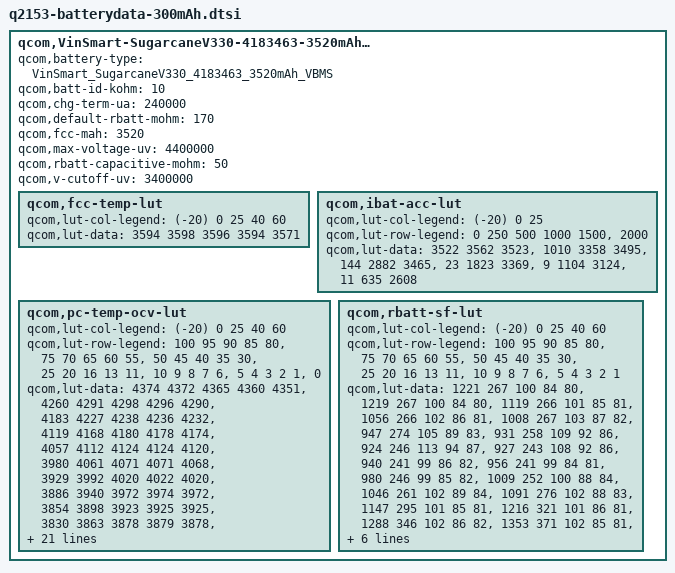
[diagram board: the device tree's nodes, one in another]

qcom,VinSmart-SugarcaneV330-4183463-3520mAh-VBMS-batterydata {
	qcom,battery-type = "VinSmart_SugarcaneV330_4183463_3520mAh_VBMS";
	qcom,batt-id-kohm = <10>;
	qcom,chg-term-ua = <240000>;
	qcom,default-rbatt-mohm = <170>;
	qcom,fcc-mah = <3520>;
	qcom,max-voltage-uv = <4400000>;
	qcom,rbatt-capacitive-mohm = <50>;
	qcom,v-cutoff-uv = <3400000>;

	qcom,fcc-temp-lut {
		qcom,lut-col-legend = <(-20) 0 25 40 60>;
		qcom,lut-data = <3594 3598 3596 3594 3571>;
	};

	qcom,ibat-acc-lut {
		qcom,lut-col-legend = <(-20) 0 25>;
		qcom,lut-row-legend = <0 250 500 1000 1500>,
					<2000>;
		qcom,lut-data = <3522 3562 3523>,
				<1010 3358 3495>,
				<144 2882 3465>,
				<23 1823 3369>,
				<9 1104 3124>,
				<11 635 2608>;
	};

	qcom,pc-temp-ocv-lut {
		qcom,lut-col-legend = <(-20) 0 25 40 60>;
		qcom,lut-row-legend = <100 95 90 85 80>,
					<75 70 65 60 55>,
					<50 45 40 35 30>,
					<25 20 16 13 11>,
					<10 9 8 7 6>,
					<5 4 3 2 1>,
					<0>;
		qcom,lut-data = <4374 4372 4365 4360 4351>,
				<4260 4291 4298 4296 4290>,
				<4183 4227 4238 4236 4232>,
				<4119 4168 4180 4178 4174>,
				<4057 4112 4124 4124 4120>,
				<3980 4061 4071 4071 4068>,
				<3929 3992 4020 4022 4020>,
				<3886 3940 3972 3974 3972>,
				<3854 3898 3923 3925 3925>,
				<3830 3863 3878 3879 3878>,
				<3811 3833 3846 3846 3846>,
				<3794 3810 3822 3822 3822>,
				<3779 3793 3802 3802 3802>,
				<3764 3780 3784 3784 3783>,
				<3750 3768 3769 3766 3760>,
				<3734 3754 3752 3744 3733>,
				<3716 3734 3734 3724 3712>,
				<3698 3714 3714 3704 3692>,
				<3682 3698 3694 3685 3674>,
				<3668 3690 3687 3680 3669>,
				<3660 3686 3686 3678 3668>,
				<3650 3682 3684 3677 3666>,
				<3636 3676 3682 3674 3664>,
				<3622 3671 3677 3670 3659>,
				<3604 3660 3668 3660 3646>,
				<3580 3638 3642 3628 3614>,
				<3549 3596 3595 3582 3568>,
				<3502 3541 3536 3522 3508>,
				<3434 3462 3456 3435 3428>,
				<3316 3340 3326 3310 3308>,
				<3000 3000 3000 3000 3000>;
	};

	qcom,rbatt-sf-lut {
		qcom,lut-col-legend = <(-20) 0 25 40 60>;
		qcom,lut-row-legend = <100 95 90 85 80>,
					<75 70 65 60 55>,
					<50 45 40 35 30>,
					<25 20 16 13 11>,
					<10 9 8 7 6>,
					<5 4 3 2 1>;
		qcom,lut-data = <1221 267 100 84 80>,
				<1219 267 100 84 80>,
				<1119 266 101 85 81>,
				<1056 266 102 86 81>,
				<1008 267 103 87 82>,
				<947 274 105 89 83>,
				<931 258 109 92 86>,
				<924 246 113 94 87>,
				<927 243 108 92 86>,
				<940 241 99 86 82>,
				<956 241 99 84 81>,
				<980 246 99 85 82>,
				<1009 252 100 88 84>,
				<1046 261 102 89 84>,
				<1091 276 102 88 83>,
				<1147 295 101 85 81>,
				<1216 321 101 86 81>,
				<1288 346 102 86 82>,
				<1353 371 102 85 81>,
				<1384 382 102 86 82>,
				<1519 399 104 87 82>,
				<1718 420 106 89 85>,
				<1961 447 108 91 87>,
				<2307 480 112 94 89>,
				<2798 517 116 95 88>,
				<3495 566 113 91 84>,
				<4634 652 114 91 84>,
				<6701 804 119 92 85>,
				<10458 1134 130 98 88>,
				<19273 2267 189 132 108>;
	};
};
